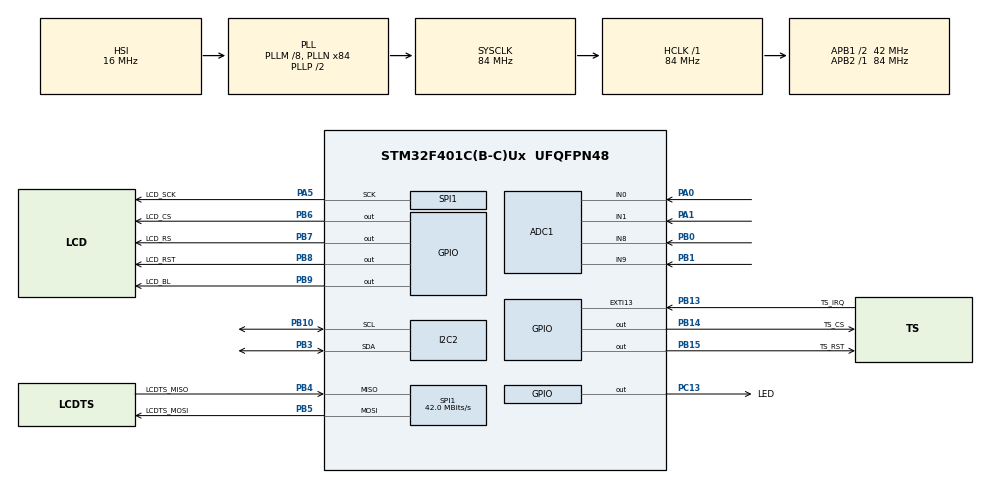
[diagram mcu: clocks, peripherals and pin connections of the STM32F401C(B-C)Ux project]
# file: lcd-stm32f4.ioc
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ADC1.Channel-0\#ChannelRegularConversion=ADC_CHANNEL_TEMPSENSOR
ADC1.Channel-1\#ChannelRegularConversion=ADC_CHANNEL_0
ADC1.Channel-2\#ChannelRegularConversion=ADC_CHANNEL_1
ADC1.Channel-3\#ChannelRegularConversion=ADC_CHANNEL_8
ADC1.ContinuousConvMode=DISABLE
ADC1.EOCSelection=ADC_EOC_SEQ_CONV
ADC1.NbrOfConversion=4
ADC1.NbrOfConversionFlag=1
ADC1.Rank-0\#ChannelRegularConversion=1
ADC1.Rank-1\#ChannelRegularConversion=2
ADC1.Rank-2\#ChannelRegularConversion=3
ADC1.Rank-3\#ChannelRegularConversion=4
ADC1.SamplingTime-0\#ChannelRegularConversion=ADC_SAMPLETIME_3CYCLES
ADC1.SamplingTime-1\#ChannelRegularConversion=ADC_SAMPLETIME_3CYCLES
ADC1.SamplingTime-2\#ChannelRegularConversion=ADC_SAMPLETIME_3CYCLES
ADC1.SamplingTime-3\#ChannelRegularConversion=ADC_SAMPLETIME_3CYCLES
ADC1.master=1
Dma.ADC1.0.Direction=DMA_PERIPH_TO_MEMORY
Dma.ADC1.0.FIFOMode=DMA_FIFOMODE_DISABLE
Dma.ADC1.0.Instance=DMA2_Stream0
Dma.ADC1.0.MemDataAlignment=DMA_MDATAALIGN_HALFWORD
Dma.ADC1.0.MemInc=DMA_MINC_ENABLE
Dma.ADC1.0.Mode=DMA_NORMAL
Dma.ADC1.0.PeriphDataAlignment=DMA_PDATAALIGN_HALFWORD
Dma.ADC1.0.PeriphInc=DMA_PINC_DISABLE
Dma.ADC1.0.Priority=DMA_PRIORITY_LOW
Dma.Request0=ADC1
I2C2.I2C_Mode=I2C_Standard
I2C2.NoStretchMode=I2C_NOSTRETCH_DISABLE
Mcu.Family=STM32F4
Mcu.Name=STM32F401C(B-C)Ux
Mcu.Package=UFQFPN48
NVIC.DMA2_Stream0_IRQn=true\:0\:0\:false\:false\:true\:false\:true\:true
NVIC.PriorityGroup=NVIC_PRIORITYGROUP_4
PA0-WKUP.Signal=ADCx_IN0
PA1.Signal=ADCx_IN1
PA13.Mode=Serial_Wire
PA13.Signal=SYS_JTMS-SWDIO
PA14.Mode=Serial_Wire
PA14.Signal=SYS_JTCK-SWCLK
PA5.GPIO_Label=LCD_SCK
PA5.Mode=Full_Duplex_Master
PA5.Signal=SPI1_SCK
PB0.Signal=ADCx_IN8
PB1.Signal=ADCx_IN9
PB10.Mode=I2C
PB10.Signal=I2C2_SCL
PB13.GPIO_Label=TS_IRQ
PB13.Signal=GPXTI13
PB14.GPIO_Label=TS_CS
PB14.Signal=GPIO_Output
PB15.GPIO_Label=TS_RST
PB15.Signal=GPIO_Output
PB3.Mode=I2C
PB3.Signal=I2C2_SDA
PB4.GPIO_Label=LCDTS_MISO
PB4.Mode=Full_Duplex_Master
PB4.Signal=SPI1_MISO
PB5.GPIO_Label=LCDTS_MOSI
PB5.Mode=Full_Duplex_Master
PB5.Signal=SPI1_MOSI
PB6.GPIO_Label=LCD_CS
PB6.Signal=GPIO_Output
PB7.GPIO_Label=LCD_RS
PB7.Signal=GPIO_Output
PB8.GPIO_Label=LCD_RST
PB8.Signal=GPIO_Output
PB9.GPIO_Label=LCD_BL
PB9.PinState=GPIO_PIN_SET
PB9.Signal=GPIO_Output
PC13-ANTI_TAMP.GPIO_Label=LED
PC13-ANTI_TAMP.Signal=GPIO_Output
ProjectManager.HeapSize=0x200
ProjectManager.StackSize=0x400
ProjectManager.TargetToolchain=CMake
RCC.48MHZClocksFreq_Value=33600000
RCC.AHBFreq_Value=84000000
RCC.APB1CLKDivider=RCC_HCLK_DIV2
RCC.APB1Freq_Value=42000000
RCC.APB1TimFreq_Value=84000000
RCC.APB2Freq_Value=84000000
RCC.APB2TimFreq_Value=84000000
RCC.CortexFreq_Value=84000000
RCC.HCLKFreq_Value=84000000
RCC.HSE_VALUE=25000000
RCC.HSI_VALUE=16000000
RCC.LSE_VALUE=32768
RCC.PLLM=8
RCC.PLLN=84
RCC.PLLQ=5
RCC.SYSCLKFreq_VALUE=84000000
RCC.SYSCLKSource=RCC_SYSCLKSOURCE_PLLCLK
RCC.VCOOutputFreq_Value=168000000
SH.ADCx_IN0.0=ADC1_IN0,IN0
SH.ADCx_IN1.0=ADC1_IN1,IN1
SH.ADCx_IN8.0=ADC1_IN8,IN8
SH.ADCx_IN9.0=ADC1_IN9,IN9
SPI1.BaudRatePrescaler=SPI_BAUDRATEPRESCALER_2
SPI1.CLKPhase=SPI_PHASE_1EDGE
SPI1.CalculateBaudRate=42.0 MBits/s
SPI1.Direction=SPI_DIRECTION_2LINES
SPI1.Mode=SPI_MODE_MASTER
SPI1.VirtualType=VM_MASTER
VP_ADC1_TempSens_Input.Mode=IN-TempSens
board=custom

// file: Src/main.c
/* USER CODE BEGIN Header */
/**
  ******************************************************************************
  * @file           : main.c
  * @brief          : Main program body
  ******************************************************************************
  * @attention
  *
  * Copyright (c) 2025 STMicroelectronics.
  * All rights reserved.
  *
  * This software is licensed under terms that can be found in the LICENSE file
  * in the root directory of this software component.
  * If no LICENSE file comes with this software, it is provided AS-IS.
  *
  ******************************************************************************
  */
/* USER CODE END Header */
#include "main.h"

/* USER CODE BEGIN Includes */
#include "debugger.h"
#include "stm32_adafruit_lcd.h"
#include "app_main.h"

/* USER CODE END Includes */

ADC_HandleTypeDef hadc1;
DMA_HandleTypeDef hdma_adc1;

I2C_HandleTypeDef hi2c2;

SPI_HandleTypeDef hspi1;

void SystemClock_Config(void);
static void MX_GPIO_Init(void);
static void MX_DMA_Init(void);
static void MX_SPI1_Init(void);
static void MX_ADC1_Init(void);
static void MX_I2C2_Init(void);
/* USER CODE BEGIN PFP */
void mainApp(void);

/* USER CODE END PFP */

int main(void)
{

  /* MCU Configuration--------------------------------------------------------*/

  /* Reset of all peripherals, Initializes the Flash interface and the Systick. */
  HAL_Init();

  /* Configure the system clock */
  SystemClock_Config();

  /* Initialize all configured peripherals */
  MX_GPIO_Init();
  MX_DMA_Init();
  MX_SPI1_Init();
  MX_ADC1_Init();
  MX_I2C2_Init();
  /* USER CODE BEGIN 2 */
  // mainApp();
  setup();
  /* USER CODE END 2 */

  /* Infinite loop */
  /* USER CODE BEGIN WHILE */
  while (1)
  {
    loop();
    /* USER CODE END WHILE */

  }
}

void SystemClock_Config(void)
{
  RCC_OscInitTypeDef RCC_OscInitStruct = {0};
  RCC_ClkInitTypeDef RCC_ClkInitStruct = {0};

  /** Configure the main internal regulator output voltage
  */
  __HAL_RCC_PWR_CLK_ENABLE();
  __HAL_PWR_VOLTAGESCALING_CONFIG(PWR_REGULATOR_VOLTAGE_SCALE2);

  /** Initializes the RCC Oscillators according to the specified parameters
  * in the RCC_OscInitTypeDef structure.
  */
  RCC_OscInitStruct.OscillatorType = RCC_OSCILLATORTYPE_HSI;
  RCC_OscInitStruct.HSIState = RCC_HSI_ON;
  RCC_OscInitStruct.HSICalibrationValue = RCC_HSICALIBRATION_DEFAULT;
  RCC_OscInitStruct.PLL.PLLState = RCC_PLL_ON;
  RCC_OscInitStruct.PLL.PLLSource = RCC_PLLSOURCE_HSI;
  RCC_OscInitStruct.PLL.PLLM = 8;
  RCC_OscInitStruct.PLL.PLLN = 84;
  RCC_OscInitStruct.PLL.PLLP = RCC_PLLP_DIV2;
  RCC_OscInitStruct.PLL.PLLQ = 5;
  if (HAL_RCC_OscConfig(&RCC_OscInitStruct) != HAL_OK)
  {
    Error_Handler();
  }

  /** Initializes the CPU, AHB and APB buses clocks
  */
  RCC_ClkInitStruct.ClockType = RCC_CLOCKTYPE_HCLK|RCC_CLOCKTYPE_SYSCLK
                              |RCC_CLOCKTYPE_PCLK1|RCC_CLOCKTYPE_PCLK2;
  RCC_ClkInitStruct.SYSCLKSource = RCC_SYSCLKSOURCE_PLLCLK;
  RCC_ClkInitStruct.AHBCLKDivider = RCC_SYSCLK_DIV1;
  RCC_ClkInitStruct.APB1CLKDivider = RCC_HCLK_DIV2;
  RCC_ClkInitStruct.APB2CLKDivider = RCC_HCLK_DIV1;

  if (HAL_RCC_ClockConfig(&RCC_ClkInitStruct, FLASH_LATENCY_2) != HAL_OK)
  {
    Error_Handler();
  }
}

static void MX_ADC1_Init(void)
{

  ADC_ChannelConfTypeDef sConfig = {0};

  /** Configure the global features of the ADC (Clock, Resolution, Data Alignment and number of conversion)
  */
  hadc1.Instance = ADC1;
  hadc1.Init.ClockPrescaler = ADC_CLOCK_SYNC_PCLK_DIV4;
  hadc1.Init.Resolution = ADC_RESOLUTION_12B;
  hadc1.Init.ScanConvMode = ENABLE;
  hadc1.Init.ContinuousConvMode = DISABLE;
  hadc1.Init.DiscontinuousConvMode = DISABLE;
  hadc1.Init.ExternalTrigConvEdge = ADC_EXTERNALTRIGCONVEDGE_NONE;
  hadc1.Init.ExternalTrigConv = ADC_SOFTWARE_START;
  hadc1.Init.DataAlign = ADC_DATAALIGN_RIGHT;
  hadc1.Init.NbrOfConversion = 4;
  hadc1.Init.DMAContinuousRequests = DISABLE;
  hadc1.Init.EOCSelection = ADC_EOC_SEQ_CONV;
  if (HAL_ADC_Init(&hadc1) != HAL_OK)
  {
    Error_Handler();
  }

  /** Configure for the selected ADC regular channel its corresponding rank in the sequencer and its sample time.
  */
  sConfig.Channel = ADC_CHANNEL_TEMPSENSOR;
  sConfig.Rank = 1;
  sConfig.SamplingTime = ADC_SAMPLETIME_3CYCLES;
  if (HAL_ADC_ConfigChannel(&hadc1, &sConfig) != HAL_OK)
  {
    Error_Handler();
  }

  /** Configure for the selected ADC regular channel its corresponding rank in the sequencer and its sample time.
  */
  sConfig.Channel = ADC_CHANNEL_0;
  sConfig.Rank = 2;
  if (HAL_ADC_ConfigChannel(&hadc1, &sConfig) != HAL_OK)
  {
    Error_Handler();
  }

  /** Configure for the selected ADC regular channel its corresponding rank in the sequencer and its sample time.
  */
  sConfig.Channel = ADC_CHANNEL_1;
  sConfig.Rank = 3;
  if (HAL_ADC_ConfigChannel(&hadc1, &sConfig) != HAL_OK)
  {
    Error_Handler();
  }

  /** Configure for the selected ADC regular channel its corresponding rank in the sequencer and its sample time.
  */
  sConfig.Channel = ADC_CHANNEL_8;
  sConfig.Rank = 4;
  if (HAL_ADC_ConfigChannel(&hadc1, &sConfig) != HAL_OK)
  {
    Error_Handler();
  }

}

static void MX_I2C2_Init(void)
{

  hi2c2.Instance = I2C2;
  hi2c2.Init.ClockSpeed = 100000;
  hi2c2.Init.DutyCycle = I2C_DUTYCYCLE_2;
  hi2c2.Init.OwnAddress1 = 0;
  hi2c2.Init.AddressingMode = I2C_ADDRESSINGMODE_7BIT;
  hi2c2.Init.DualAddressMode = I2C_DUALADDRESS_DISABLE;
  hi2c2.Init.OwnAddress2 = 0;
  hi2c2.Init.GeneralCallMode = I2C_GENERALCALL_DISABLE;
  hi2c2.Init.NoStretchMode = I2C_NOSTRETCH_DISABLE;
  if (HAL_I2C_Init(&hi2c2) != HAL_OK)
  {
    Error_Handler();
  }

}

static void MX_SPI1_Init(void)
{

  /* SPI1 parameter configuration*/
  hspi1.Instance = SPI1;
  hspi1.Init.Mode = SPI_MODE_MASTER;
  hspi1.Init.Direction = SPI_DIRECTION_2LINES;
  hspi1.Init.DataSize = SPI_DATASIZE_8BIT;
  hspi1.Init.CLKPolarity = SPI_POLARITY_LOW;
  hspi1.Init.CLKPhase = SPI_PHASE_1EDGE;
  hspi1.Init.NSS = SPI_NSS_SOFT;
  hspi1.Init.BaudRatePrescaler = SPI_BAUDRATEPRESCALER_2;
  hspi1.Init.FirstBit = SPI_FIRSTBIT_MSB;
  hspi1.Init.TIMode = SPI_TIMODE_DISABLE;
  hspi1.Init.CRCCalculation = SPI_CRCCALCULATION_DISABLE;
  hspi1.Init.CRCPolynomial = 10;
  if (HAL_SPI_Init(&hspi1) != HAL_OK)
  {
    Error_Handler();
  }

}

static void MX_DMA_Init(void)
{

  /* DMA controller clock enable */
  __HAL_RCC_DMA2_CLK_ENABLE();

  /* DMA interrupt init */
  /* DMA2_Stream0_IRQn interrupt configuration */
  HAL_NVIC_SetPriority(DMA2_Stream0_IRQn, 0, 0);
  HAL_NVIC_EnableIRQ(DMA2_Stream0_IRQn);

}

static void MX_GPIO_Init(void)
{
  GPIO_InitTypeDef GPIO_InitStruct = {0};

  /* GPIO Ports Clock Enable */
  __HAL_RCC_GPIOC_CLK_ENABLE();
  __HAL_RCC_GPIOA_CLK_ENABLE();
  __HAL_RCC_GPIOB_CLK_ENABLE();

  /*Configure GPIO pin Output Level */
  HAL_GPIO_WritePin(LED_GPIO_Port, LED_Pin, GPIO_PIN_RESET);

  /*Configure GPIO pin Output Level */
  HAL_GPIO_WritePin(GPIOB, TS_CS_Pin|TS_RST_Pin|LCD_CS_Pin|LCD_RS_Pin
                          |LCD_RST_Pin, GPIO_PIN_RESET);

  /*Configure GPIO pin Output Level */
  HAL_GPIO_WritePin(LCD_BL_GPIO_Port, LCD_BL_Pin, GPIO_PIN_SET);

  /*Configure GPIO pin : LED_Pin */
  GPIO_InitStruct.Pin = LED_Pin;
  GPIO_InitStruct.Mode = GPIO_MODE_OUTPUT_PP;
  GPIO_InitStruct.Pull = GPIO_NOPULL;
  GPIO_InitStruct.Speed = GPIO_SPEED_FREQ_LOW;
  HAL_GPIO_Init(LED_GPIO_Port, &GPIO_InitStruct);

  /*Configure GPIO pin : TS_IRQ_Pin */
  GPIO_InitStruct.Pin = TS_IRQ_Pin;
  GPIO_InitStruct.Mode = GPIO_MODE_IT_RISING;
  GPIO_InitStruct.Pull = GPIO_NOPULL;
  HAL_GPIO_Init(TS_IRQ_GPIO_Port, &GPIO_InitStruct);

  /*Configure GPIO pins : TS_CS_Pin TS_RST_Pin LCD_CS_Pin LCD_RS_Pin
                           LCD_RST_Pin LCD_BL_Pin */
  GPIO_InitStruct.Pin = TS_CS_Pin|TS_RST_Pin|LCD_CS_Pin|LCD_RS_Pin
                          |LCD_RST_Pin|LCD_BL_Pin;
  GPIO_InitStruct.Mode = GPIO_MODE_OUTPUT_PP;
  GPIO_InitStruct.Pull = GPIO_NOPULL;
  GPIO_InitStruct.Speed = GPIO_SPEED_FREQ_LOW;
  HAL_GPIO_Init(GPIOB, &GPIO_InitStruct);

}

void Error_Handler(void)
{
  __disable_irq();
  while (1)
  {
  }
}
